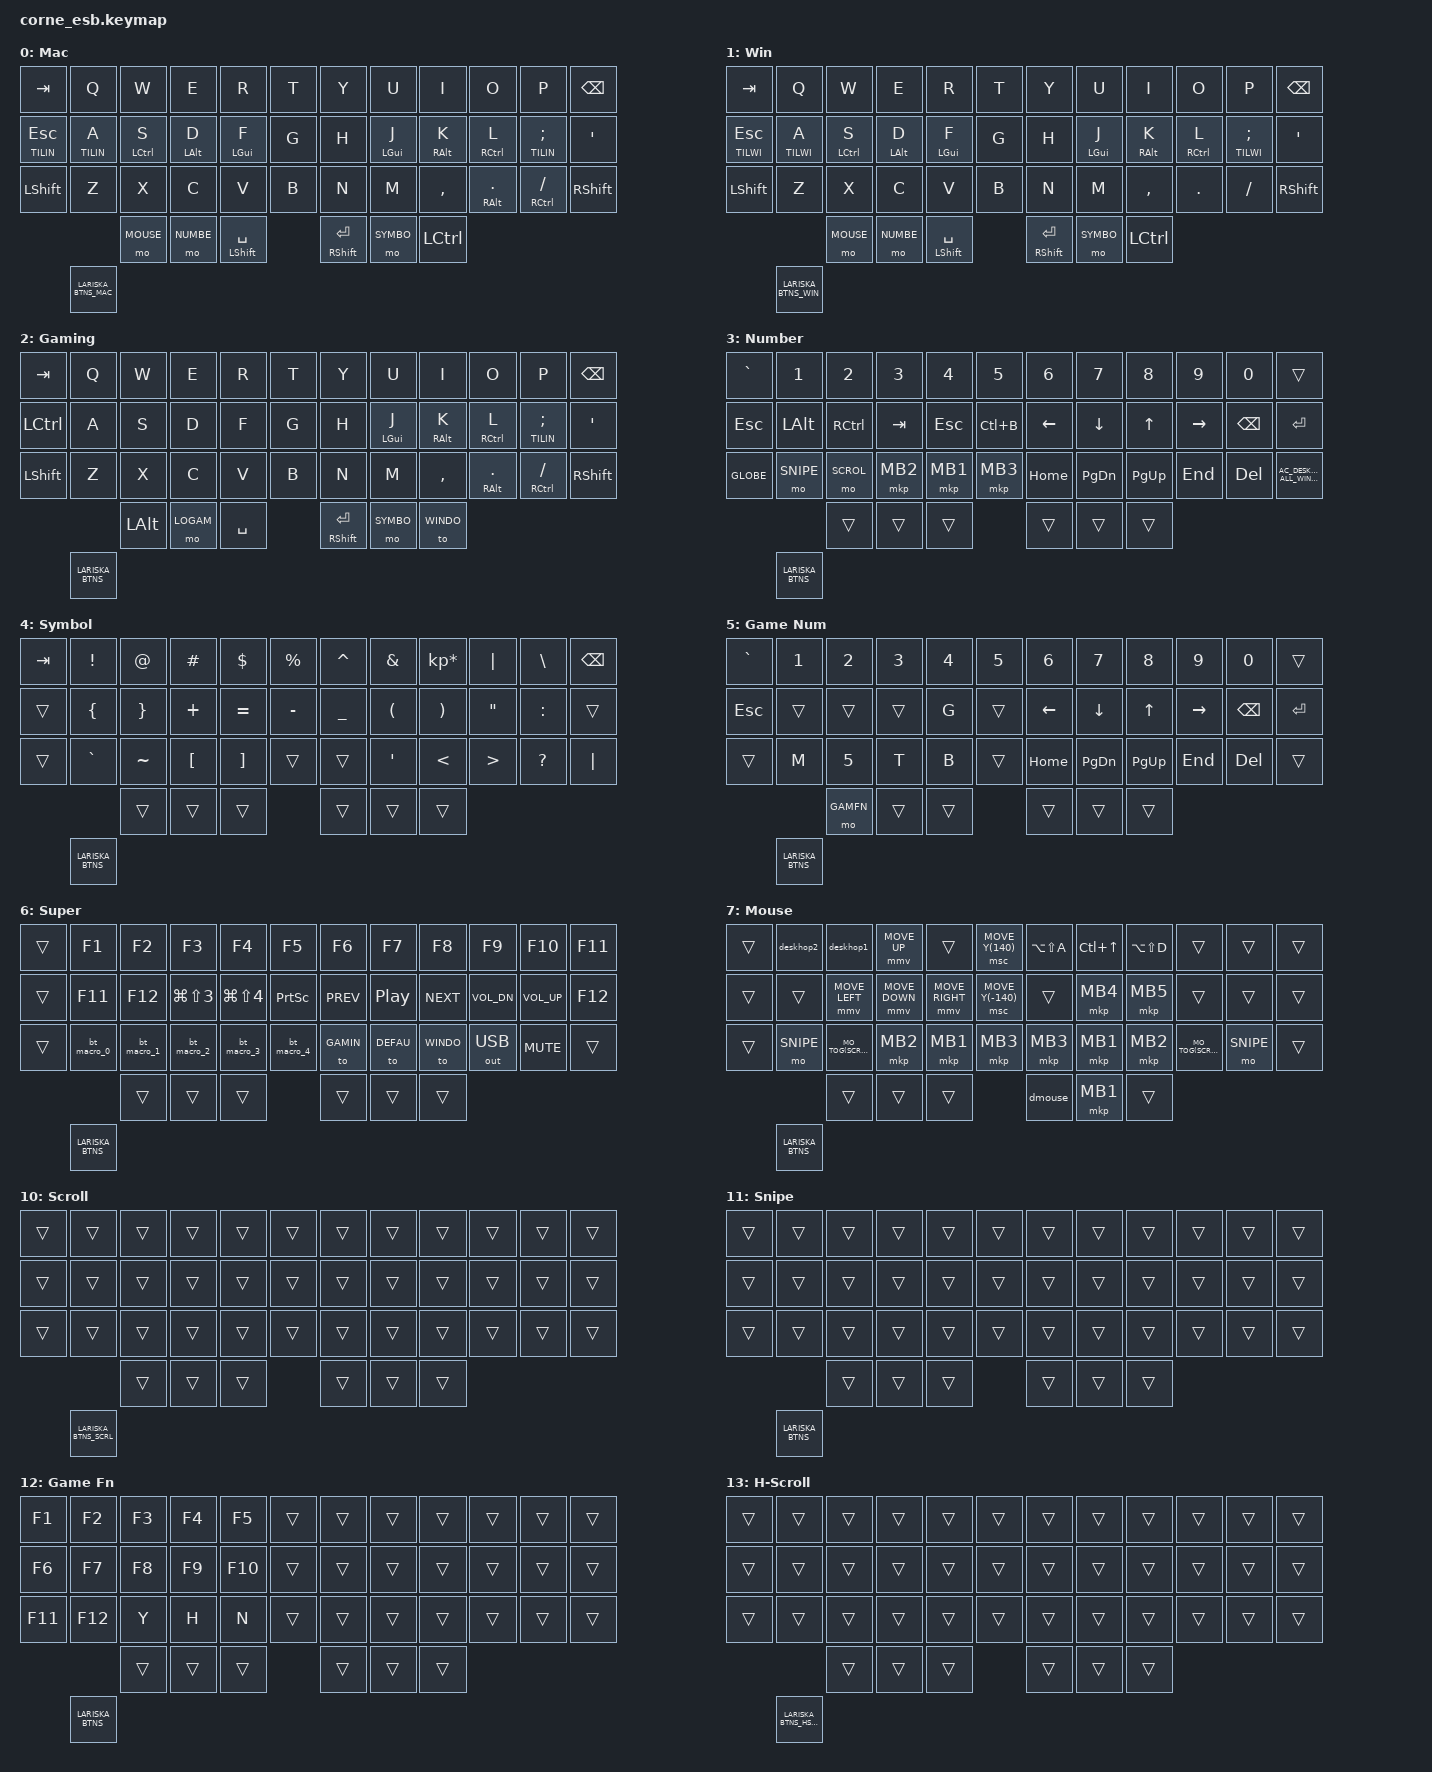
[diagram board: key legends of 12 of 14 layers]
#define ZMK_POINTING_DEFAULT_SCRL_VAL 100

#include <behaviors.dtsi>
#include <dt-bindings/zmk/keys.h>
#include <dt-bindings/zmk/bt.h>
#include <dt-bindings/zmk/ext_power.h>
#include <dt-bindings/zmk/mouse.h>
#include <dt-bindings/zmk/outputs.h>
#include <dt-bindings/zmk/pointing.h>
#include <behaviors/mouse_keys.dtsi>

#define MO_TOG(layer) &mo_tog layer layer

#define DEFAU 0
#define WINDO 1
#define GAMIN 2
#define NUMBE 3
#define SYMBO 4
#define LOGAM 5
#define SUPER 6
#define MOUSE 7
#define TILIN 8
#define TILWI 9
#define SCROL 10
#define SNIPE 11
#define GAMFN 12
#define HSCRL 13

/* Corne key positions: row 0 = 0-11, row 1 = 12-23, row 2 = 24-35,
 * thumbs = 36-38 (left) / 39-41 (right).
 *
 * Lariska (optional) mouse button bindings appended to every layer
 * (positions 42-46): LCLK RCLK MCLK MB4 MB5.
 * MB4 is a tap-dance: tap = normal MB4 click, hold = momentary SCROL layer
 * (fast 4x vertical scroll on the encoder), double-tap = OS overview (mission
 * control on mac / task view on win).
 * MB5 is a hold-tap: tap = normal MB5 click, hold = momentary tiling layer
 * (alt-tab on the scroll wheel) -- instant, no tap-dance delay.
 * Holding MB4 + MB5 together activates the horizontal-scroll layer (HSCRL):
 * the second button is &trans on the first button's layer, so it falls through
 * to its base hold; with both holds down, conditional_layers turns on HSCRL.
 * When no Lariska is paired these positions simply never fire. */
/* L/R clicks use &bd (drain-aware, zmk-behavior-button-direct, declared in
 * corne_esb_addr.dtsi): a release lost over ESB self-heals on the next click
 * instead of sticking the HID button until dongle restart. */
#define LARISKA_BTNS       &bd LCLK &bd RCLK &mkp MCLK &mo_mkp SCROL MB4 &mkp MB5
#define LARISKA_BTNS_MAC   &bd LCLK &bd RCLK &mkp MCLK &td_mb4_mac &mo_mkp TILIN MB5
#define LARISKA_BTNS_WIN   &bd LCLK &bd RCLK &mkp MCLK &td_mb4_win &mo_mkp TILWI MB5
/* Inside the held tiling layers MB4 is &trans so a second MB4 press falls
 * through to the base MB4 hold (mo_mkp SCROL via the tap-dance); SCROL + the
 * tiling layer then trigger HSCRL through conditional_layers.
 * (OS overview now lives on the MB4 double-tap.) */
#define LARISKA_BTNS_TILIN &bd LCLK &bd RCLK &mkp MCLK &trans &mkp MB5
#define LARISKA_BTNS_TILWI &bd LCLK &bd RCLK &mkp MCLK &trans &mkp MB5
/* Inside the SCROL layer MB5 is &trans so it falls through to the base MB5
 * hold (mo_mkp TILIN/TILWI); SCROL + tiling then trigger HSCRL. */
#define LARISKA_BTNS_SCRL  &bd LCLK &bd RCLK &mkp MCLK &mo_mkp SCROL MB4 &trans
/* MB4 + MB5 held: both fall through (&trans) so the holds persist. */
#define LARISKA_BTNS_HSCRL &bd LCLK &bd RCLK &mkp MCLK &trans &trans

/ {
    /* One discrete REL_WHEEL tick per Lariska encoder detent via
     * zmk-behavior-stepped-scroll. stepped_scroll is defined in the addr dtsi;
     * stepped_scroll_il (dongle overlay) routes its events to HID. */
    lariska_scroll: lariska_scroll {
        compatible = "zmk,behavior-sensor-rotate";
        #sensor-binding-cells = <0>;
        bindings = <&stepped_scroll (-1)>, <&stepped_scroll 1>;
    };
    /* Fast vertical scroll (4x) for the MB4-hold scroll layer: 4 REL_WHEEL
     * ticks per detent, same direction as lariska_scroll. */
    lariska_scroll_4x: lariska_scroll_4x {
        compatible = "zmk,behavior-sensor-rotate";
        #sensor-binding-cells = <0>;
        bindings = <&stepped_scroll (-4)>, <&stepped_scroll 4>;
    };
    /* Horizontal mouse-wheel scroll for the MB4+MB5 hscroll layer. One
     * REL_HWHEEL tick per detent via stepped_hscroll (addr dtsi / overlay). */
    lariska_hscroll: lariska_hscroll {
        compatible = "zmk,behavior-sensor-rotate";
        #sensor-binding-cells = <0>;
        bindings = <&stepped_hscroll (-1)>, <&stepped_hscroll 1>;
    };
    alt_tab_encoder: alt_tab_encoder {
        compatible = "zmk,behavior-sensor-rotate";
        label = "ALT_TAB_ENC";
        #sensor-binding-cells = <0>;
        tap-ms = <5>;
        bindings = <&swap_enc_rev>, <&swap_enc>;
    };
    /* Mouse-wheel space navigation for the Mac tiling layer. */
    lariska_ws: lariska_ws {
        compatible = "zmk,behavior-sensor-rotate";
        label = "LARISKA_WS";
        #sensor-binding-cells = <0>;
        tap-ms = <5>;
        bindings = <&kp LC(RIGHT)>, <&kp LC(LEFT)>;
    };
    rot_kp: sensor_rotate_kp {
        compatible = "zmk,behavior-sensor-rotate-var";
        #sensor-binding-cells = <2>;
        bindings = <&kp>, <&kp>;
    };

    conditional_layers {
        compatible = "zmk,conditional-layers";

        tri_layer {
            if-layers = <NUMBE SYMBO>;
            then-layer = <SUPER>;
        };

        tri_layer_gaming {
            if-layers = <SYMBO LOGAM>;
            then-layer = <SUPER>;
        };

        /* MB4 (SCROL) + MB5 (tiling) held together -> horizontal scroll. */
        hscroll_mac {
            if-layers = <SCROL TILIN>;
            then-layer = <HSCRL>;
        };

        hscroll_win {
            if-layers = <SCROL TILWI>;
            then-layer = <HSCRL>;
        };
    };

    behaviors {
        sk_forever: sk_forever {
            compatible = "zmk,behavior-sticky-key";
            #binding-cells = <1>;
            bindings = <&kp>;
            ignore-modifiers;
            release-after-ms = <600000>;
        };

        hm: homerow_mods {
            compatible = "zmk,behavior-hold-tap";
            label = "HOMEROW_MODS";
            #binding-cells = <2>;
            tapping-term-ms = <200>;
            quick-tap-ms = <0>;
            flavor = "tap-preferred";
            bindings = <&kp>, <&kp>;
        };

        hk: homerow_hold {
            compatible = "zmk,behavior-hold-tap";
            label = "HOLD_MOD";
            #binding-cells = <2>;
            tapping-term-ms = <150>;
            quick-tap-ms = <0>;
            flavor = "hold-preferred";
            bindings = <&kp>, <&kp>;
        };

        hs: hold_custom {
            compatible = "zmk,behavior-hold-tap";
            label = "HOLD_CUSTOM";
            #binding-cells = <2>;
            tapping-term-ms = <500>;
            quick-tap-ms = <0>;
            flavor = "tap-preferred";
            bindings = <&kp>, <&kp>;
        };

        mo_tog: behavior_mo_tog {
            compatible = "zmk,behavior-hold-tap";
            #binding-cells = <2>;
            flavor = "hold-preferred";
            tapping-term-ms = <200>;
            bindings = <&mo>, <&tog>;
        };

        /* Hold = momentary layer, tap = mouse-button click (for MB5). */
        mo_mkp: behavior_mo_mkp {
            compatible = "zmk,behavior-hold-tap";
            label = "MO_MKP";
            #binding-cells = <2>;
            flavor = "hold-preferred";
            tapping-term-ms = <150>;
            quick-tap-ms = <0>;
            bindings = <&mo>, <&mkp>;
        };

        w1: w1 {
            compatible = "zmk,behavior-tri-state";
            label = "WIN OPEN 1";
            #binding-cells = <0>;
            bindings = <&kt LGUI>, <&kp N1>, <&kt LGUI>;
        };

        w2: w2 {
            compatible = "zmk,behavior-tri-state";
            label = "WIN OPEN 2";
            #binding-cells = <0>;
            bindings = <&kt LGUI>, <&kp N2>, <&kt LGUI>;
        };

        w3: w3 {
            compatible = "zmk,behavior-tri-state";
            label = "WIN OPEN 3";
            #binding-cells = <0>;
            bindings = <&kt LGUI>, <&kp N3>, <&kt LGUI>;
        };

        w4: w4 {
            compatible = "zmk,behavior-tri-state";
            label = "WIN OPEN 4";
            #binding-cells = <0>;
            bindings = <&kt LGUI>, <&kp N4>, <&kt LGUI>;
        };

        w5: w5 {
            compatible = "zmk,behavior-tri-state";
            label = "WIN OPEN 5";
            #binding-cells = <0>;
            bindings = <&kt LGUI>, <&kp N5>, <&kt LGUI>;
        };

        w6: w6 {
            compatible = "zmk,behavior-tri-state";
            label = "WIN OPEN 6";
            #binding-cells = <0>;
            bindings = <&kt LGUI>, <&kp N6>, <&kt LGUI>;
        };

        w7: w7 {
            compatible = "zmk,behavior-tri-state";
            label = "WIN OPEN 7";
            #binding-cells = <0>;
            bindings = <&kt LGUI>, <&kp N7>, <&kt LGUI>;
        };

        w8: w8 {
            compatible = "zmk,behavior-tri-state";
            label = "WIN OPEN 8";
            #binding-cells = <0>;
            bindings = <&kt LGUI>, <&kp N8>, <&kt LGUI>;
        };

        w9: w9 {
            compatible = "zmk,behavior-tri-state";
            label = "WIN OPEN 9";
            #binding-cells = <0>;
            bindings = <&kt LGUI>, <&kp N9>, <&kt LGUI>;
        };

        td_alt: tap_dance_0 {
            compatible = "zmk,behavior-tap-dance";
            #binding-cells = <0>;
            tapping-term-ms = <200>;
            bindings = <&kp LALT>, <&to WINDO>;
        };

        td_mo: tap_dance_1 {
            compatible = "zmk,behavior-tap-dance";
            #binding-cells = <0>;
            tapping-term-ms = <200>;
            bindings = <MO_TOG(MOUSE)>, <&to GAMIN>;
        };

        /* Lariska MB4 tap-dance: tap = MB4 click, hold = momentary SCROL layer
         * (fast 4x vertical scroll), double-tap = OS overview (mission control /
         * task view). Binding 0 is the existing hold-tap, so it still resolves
         * tap-vs-hold; binding 1 fires only on the second tap. The tap-dance
         * delay lands on the scroll layer (not on MB5's alt-tab, now instant). */
        td_mb4_mac: td_mb4_mac {
            compatible = "zmk,behavior-tap-dance";
            #binding-cells = <0>;
            tapping-term-ms = <200>;
            bindings = <&mo_mkp SCROL MB4>, <&kp LC(UP)>;
        };
        td_mb4_win: td_mb4_win {
            compatible = "zmk,behavior-tap-dance";
            #binding-cells = <0>;
            tapping-term-ms = <200>;
            bindings = <&mo_mkp SCROL MB4>, <&kp LG(TAB)>;
        };

        /* Forward alt-tab on the windows tiling layer. hold-start makes swap and
         * swap_rev share a ref-counted LALT, so either can start the alt-tab from
         * cold and they compose while cycling. ignores the swap_rev key (pos 26)
         * and Lariska LCLK/RCLK/MCLK (42-44) so a click doesn't end the hold. */
        swap: swapper {
            compatible = "zmk,behavior-tri-state";
            label = "SWAPPER";
            #binding-cells = <0>;
            bindings = <&kp LALT>, <&kp TAB>, <&kp LALT>;
            hold-start;
            ignored-key-positions = <26 42 43 44>;
        };
        /* Reverse alt-tab (Shift+Tab); shares the LALT hold with swap (pos 14). */
        swap_rev: swap_rev {
            compatible = "zmk,behavior-tri-state";
            label = "SWAPPER_REV";
            #binding-cells = <0>;
            bindings = <&kp LALT>, <&kp LS(TAB)>, <&kp LALT>;
            hold-start;
            ignored-key-positions = <14 42 43 44>;
        };

        /* Forward cmd-tab on the Mac tiling layer; ignores swapmac_rev (pos 25). */
        swapmac: swappermac {
            compatible = "zmk,behavior-tri-state";
            label = "SWAPPERMAC";
            #binding-cells = <0>;
            bindings = <&kp LGUI>, <&kp TAB>, <&kp LGUI>;
            hold-start;
            ignored-key-positions = <25 42 43 44>;
        };
        /* Reverse cmd-tab; shares the LGUI hold with swapmac (pos 27). */
        swapmac_rev: swapmac_rev {
            compatible = "zmk,behavior-tri-state";
            label = "SWAPPERMAC_REV";
            #binding-cells = <0>;
            bindings = <&kp LGUI>, <&kp LS(TAB)>, <&kp LGUI>;
            hold-start;
            ignored-key-positions = <27 42 43 44>;
        };

        /* Encoder-driven alt-tab for the Lariska wheel on the Windows tiling layer.
         * swap_enc / swap_enc_rev share the alt-hold via the sensor's virtual key
         * position, so alt-tab engages no matter which way the wheel turns first.
         * ignored-key-positions 42-44 = Lariska LCLK/RCLK/MCLK, so clicking
         * mid-cycle doesn't interrupt the hold. */
        swap_enc: swap_enc {
            compatible = "zmk,behavior-tri-state";
            label = "SWAPPER_ENC";
            #binding-cells = <0>;
            bindings = <&kt LALT>, <&kp TAB>, <&kt LALT>;
            ignored-key-positions = <42 43 44>;
        };
        swap_enc_rev: swap_enc_rev {
            compatible = "zmk,behavior-tri-state";
            label = "SWAPPER_ENC_REV";
            #binding-cells = <0>;
            bindings = <&kt LALT>, <&kp LS(TAB)>, <&kt LALT>;
            ignored-key-positions = <42 43 44>;
        };
    };

    macros {
        bt_macro_0: bt_macro_0 {
            label = "esb_macro_0";
            compatible = "zmk,behavior-macro";
            #binding-cells = <0>;
            wait-ms = <0>;
            tap-ms = <0>;
            bindings = <&to DEFAU>;
        };

        bt_macro_1: bt_macro_1 {
            label = "esb_macro_1";
            compatible = "zmk,behavior-macro";
            #binding-cells = <0>;
            wait-ms = <0>;
            tap-ms = <0>;
            bindings = <&to WINDO>;
        };

        bt_macro_2: bt_macro_2 {
            label = "esb_macro_2";
            compatible = "zmk,behavior-macro";
            #binding-cells = <0>;
            wait-ms = <0>;
            tap-ms = <0>;
            bindings = <&to GAMIN>;
        };

        bt_macro_3: bt_macro_3 {
            label = "esb_macro_3";
            compatible = "zmk,behavior-macro";
            #binding-cells = <0>;
            wait-ms = <0>;
            tap-ms = <0>;
            bindings = <&out OUT_USB>;
        };

        bt_macro_4: bt_macro_4 {
            label = "esb_macro_4";
            compatible = "zmk,behavior-macro";
            #binding-cells = <0>;
            wait-ms = <0>;
            tap-ms = <0>;
            bindings = <&none>;
        };

        dmouse: dmouse {
            label = "deactivate_mouse";
            compatible = "zmk,behavior-macro";
            #binding-cells = <0>;
            wait-ms = <0>;
            tap-ms = <0>;
            bindings = <&mo MOUSE>, <&mo SCROL>, <&mo SNIPE>;
        };

        deskhop1: deskhop1 {
            label = "deskhop1";
            compatible = "zmk,behavior-macro";
            #binding-cells = <0>;
            wait-ms = <0>;
            tap-ms = <0>;
            bindings = <&kp RC(RA(N1))>;
        };

        deskhop2: deskhop2 {
            label = "deskhop2";
            compatible = "zmk,behavior-macro";
            #binding-cells = <0>;
            wait-ms = <0>;
            tap-ms = <0>;
            bindings = <&kp RC(RA(N2))>;
        };
    };

    combos {
        compatible = "zmk,combos";

        /* X + C + V (positions 26 27 28) toggles gaming, only from the
         * windows base layer or gaming itself. */
        combo_gaming {
            timeout-ms = <50>;
            key-positions = <26 27 28>;
            bindings = <&tog GAMIN>;
            layers = <GAMIN WINDO>;
        };
    };

    keymap {
        compatible = "zmk,keymap";

        default_layer {
            label = "Mac";
            bindings = <
&kp TAB        &kp Q        &kp W        &kp E       &kp R       &kp T         &kp Y          &kp U       &kp I       &kp O         &kp P           &kp BSPC
&lt TILIN ESC  &lt TILIN A  &hm LCTRL S  &hm LALT D  &hm LGUI F  &kp G         &kp H          &hm LGUI J  &hm RALT K  &hm RCTRL L   &lt TILIN SEMI  &kp SQT
&kp LSHFT      &kp Z        &kp X        &kp C       &kp V       &kp B         &kp N          &kp M       &kp COMMA   &hm RALT DOT  &hm RCTRL FSLH  &kp RSHFT
                                &mo MOUSE   &mo NUMBE  &hm LSHFT SPACE    &hk RSHFT RET  &mo SYMBO  &kp LCTRL
            LARISKA_BTNS_MAC
            >;
            sensor-bindings = <&lariska_scroll>;
        };

        windows {
            label = "Win";
            bindings = <
&kp TAB        &kp Q        &kp W        &kp E       &kp R       &kp T         &kp Y          &kp U       &kp I       &kp O         &kp P           &kp BSPC
&lt TILWI ESC  &lt TILWI A  &hm LCTRL S  &hm LALT D  &hm LGUI F  &kp G         &kp H          &hm LGUI J  &hm RALT K  &hm RCTRL L   &lt TILWI SEMI  &kp SQT
&kp LSHFT      &kp Z        &kp X        &kp C       &kp V       &kp B         &kp N          &kp M       &kp COMMA   &kp DOT       &kp FSLH        &kp RSHFT
                                &mo MOUSE   &mo NUMBE  &hm LSHFT SPACE    &hk RSHFT RET  &mo SYMBO  &kp LCTRL
            LARISKA_BTNS_WIN
            >;
            sensor-bindings = <&lariska_scroll>;
        };

        gaming_layer {
            label = "Gaming";
            bindings = <
&kp TAB    &kp Q  &kp W  &kp E  &kp R  &kp T        &kp Y      &kp U       &kp I       &kp O         &kp P           &kp BSPC
&kp LCTRL  &kp A  &kp S  &kp D  &kp F  &kp G        &kp H      &hm LGUI J  &hm RALT K  &hm RCTRL L   &lt TILIN SEMI  &kp SQT
&kp LSHFT  &kp Z  &kp X  &kp C  &kp V  &kp B        &kp N      &kp M       &kp COMMA   &hm RALT DOT  &hm RCTRL FSLH  &kp RSHFT
                     &kp LALT  &mo LOGAM  &kp SPACE    &hk RSHFT RET  &mo SYMBO  &to WINDO
            LARISKA_BTNS
            >;
            sensor-bindings = <&lariska_scroll>;
        };

        lower_layer {
            label = "Number";
            bindings = <
&kp GRAVE  &kp N1     &kp N2     &kp N3    &kp N4    &kp N5       &kp N6    &kp N7     &kp N8     &kp N9     &kp N0    &trans
&kp ESC    &kp LALT   &kp RCTRL  &kp TAB   &kp ESC   &kp LC(B)    &kp LEFT  &kp DOWN   &kp UP     &kp RIGHT  &kp BSPC  &kp RET
&kp GLOBE  &mo SNIPE  &mo SCROL  &mkp MB2  &mkp MB1  &mkp MB3     &kp HOME  &kp PG_DN  &kp PG_UP  &kp END    &kp DEL   &kp C_AC_DESKTOP_SHOW_ALL_WINDOWS
                                  &trans  &trans  &trans    &trans  &trans  &trans
            LARISKA_BTNS
            >;
            sensor-bindings = <&lariska_scroll>;
        };

        raise_layer {
            label = "Symbol";
            bindings = <
&kp TAB  &kp EXCL   &kp AT     &kp HASH  &kp DLLR   &kp PRCNT    &kp CARET  &kp AMPS  &kp KP_MULTIPLY  &kp PIPE  &kp BSLH   &kp BSPC
&trans   &kp LBRC   &kp RBRC   &kp PLUS  &kp EQUAL  &kp MINUS    &kp UNDER  &kp LPAR  &kp RPAR         &kp DQT   &kp COLON  &trans
&trans   &kp GRAVE  &kp TILDE  &kp LBKT  &kp RBKT   &trans       &trans     &kp SQT   &kp LT           &kp GT    &kp QMARK  &kp PIPE
                                  &trans  &trans  &trans    &trans  &trans  &trans
            LARISKA_BTNS
            >;
            sensor-bindings = <&lariska_scroll>;
        };

        gaming_lower {
            label = "Game Num";
            bindings = <
&kp GRAVE  &kp N1  &kp N2  &kp N3  &kp N4  &kp N5    &kp N6    &kp N7     &kp N8     &kp N9     &kp N0    &trans
&kp ESC    &trans  &trans  &trans  &kp G   &trans    &kp LEFT  &kp DOWN   &kp UP     &kp RIGHT  &kp BSPC  &kp RET
&trans     &kp M   &kp N5  &kp T   &kp B   &trans    &kp HOME  &kp PG_DN  &kp PG_UP  &kp END    &kp DEL   &trans
                     &mo GAMFN  &trans  &trans    &trans  &trans  &trans
            LARISKA_BTNS
            >;
            sensor-bindings = <&lariska_scroll>;
        };

        super_layer {
            label = "Super";
            bindings = <
&trans  &kp F1       &kp F2       &kp F3          &kp F4          &kp F5         &kp F6      &kp F7     &kp F8      &kp F9        &kp F10       &kp F11
&trans  &kp F11      &kp F12      &kp LG(LS(N3))  &kp LG(LS(N4))  &kp PSCRN      &kp C_PREV  &kp C_PP   &kp C_NEXT  &kp C_VOL_DN  &kp C_VOL_UP  &kp F12
&trans  &bt_macro_0  &bt_macro_1  &bt_macro_2     &bt_macro_3     &bt_macro_4    &to GAMIN   &to DEFAU  &to WINDO   &out OUT_USB  &kp C_MUTE    &trans
                                     &trans  &trans  &trans    &trans  &trans  &trans
            LARISKA_BTNS
            >;
        };

        mouse_layer {
            label = "Mouse";
            bindings = <
&trans  &deskhop2  &deskhop1       &mmv MOVE_UP    &trans           &msc MOVE_Y(140)     &kp LA(LS(A))  &kp LC(UP)  &kp LA(LS(D))  &trans         &trans     &trans
&trans  &trans     &mmv MOVE_LEFT  &mmv MOVE_DOWN  &mmv MOVE_RIGHT  &msc MOVE_Y(-140)    &trans         &mkp MB4    &mkp MB5       &trans         &trans     &trans
&trans  &mo SNIPE  MO_TOG(SCROL)   &mkp MB2        &mkp MB1         &mkp MB3             &mkp MB3       &mkp MB1    &mkp MB2       MO_TOG(SCROL)  &mo SNIPE  &trans
                                      &trans  &trans  &trans    &dmouse  &mkp MB1  &trans
            LARISKA_BTNS
            >;
            /* Lariska encoder = volume on the mouse layer. */
            sensor-bindings = <&rot_kp C_VOL_DN C_VOL_UP>;
        };

        tiling_layer {
            label = "Tiling";
            bindings = <
&trans  &hs LC(LA(LS(N1))) LA(LS(N1))  &hs LC(LA(LS(N2))) LA(LS(N2))  &hs LC(LA(LS(N3))) LA(LS(N3))  &hs LC(LA(LS(N4))) LA(LS(N4))  &hs LC(LA(LS(N5))) LA(LS(N5))    &hs LC(LA(LS(N6))) LA(LS(N6))  &hs LC(LA(LS(N7))) LA(LS(N7))  &hs LC(LA(LS(N8))) LA(LS(N8))  &hs LC(LA(LS(N9))) LA(LS(N9))  &trans  &trans
&trans  &trans                         &kp LC(F4)                     &hs LC(LA(LS(E))) LA(LS(E))    &hs LC(LA(LS(R))) LA(LS(R))    &hs LC(LA(LS(T))) LA(LS(T))      &trans                         &trans                         &trans                         &trans                         &trans  &trans
&trans  &swapmac_rev                   &kp LS(LC(F4))                 &swapmac                       &trans                         &trans                           &trans                         &trans                         &trans                         &trans                         &trans  &trans
                                          &trans  &trans  &kp LG(SPACE)    &trans  &trans  &trans
            LARISKA_BTNS_TILIN
            >;
            sensor-bindings = <&lariska_ws>;
        };

        tiling_win_layer {
            label = "TWin";
            bindings = <
&trans  &w1            &w2        &w3                          &w4                          &w5                              &w6     &w7     &w8     &w9     &trans  &trans
&trans  &trans         &swap      &hs LC(LA(LS(E))) LA(LS(E))  &hs LC(LA(LS(R))) LA(LS(R))  &hs LC(LA(LS(T))) LA(LS(T))      &trans  &trans  &trans  &trans  &trans  &trans
&trans  &kp LA(LS(D))  &swap_rev  &kp LA(LS(D))                &trans                       &trans                           &trans  &trans  &trans  &trans  &trans  &trans
                                     &trans  &trans  &kp LGUI    &trans  &trans  &trans
            LARISKA_BTNS_TILWI
            >;
            sensor-bindings = <&alt_tab_encoder>;
        };

        scroll {
            label = "Scroll";
            bindings = <
&trans  &trans  &trans  &trans  &trans  &trans    &trans  &trans  &trans  &trans  &trans  &trans
&trans  &trans  &trans  &trans  &trans  &trans    &trans  &trans  &trans  &trans  &trans  &trans
&trans  &trans  &trans  &trans  &trans  &trans    &trans  &trans  &trans  &trans  &trans  &trans
                          &trans  &trans  &trans    &trans  &trans  &trans
            LARISKA_BTNS_SCRL
            >;
            /* Fast (4x) vertical scroll on the Lariska encoder. */
            sensor-bindings = <&lariska_scroll_4x>;
        };

        snipe {
            label = "Snipe";
            bindings = <
&trans  &trans  &trans  &trans  &trans  &trans    &trans  &trans  &trans  &trans  &trans  &trans
&trans  &trans  &trans  &trans  &trans  &trans    &trans  &trans  &trans  &trans  &trans  &trans
&trans  &trans  &trans  &trans  &trans  &trans    &trans  &trans  &trans  &trans  &trans  &trans
                          &trans  &trans  &trans    &trans  &trans  &trans
            LARISKA_BTNS
            >;
        };

        game_fn_layer {
            label = "Game Fn";
            bindings = <
&kp F1   &kp F2   &kp F3  &kp F4  &kp F5   &trans     &trans  &trans  &trans  &trans  &trans  &trans
&kp F6   &kp F7   &kp F8  &kp F9  &kp F10  &trans     &trans  &trans  &trans  &trans  &trans  &trans
&kp F11  &kp F12  &kp Y   &kp H   &kp N    &trans     &trans  &trans  &trans  &trans  &trans  &trans
                          &trans  &trans  &trans    &trans  &trans  &trans
            LARISKA_BTNS
            >;
            /* Lariska encoder = volume on the gaming fn layer. */
            sensor-bindings = <&rot_kp C_VOL_DN C_VOL_UP>;
        };

        hscroll_layer {
            label = "H-Scroll";
            bindings = <
&trans  &trans  &trans  &trans  &trans  &trans    &trans  &trans  &trans  &trans  &trans  &trans
&trans  &trans  &trans  &trans  &trans  &trans    &trans  &trans  &trans  &trans  &trans  &trans
&trans  &trans  &trans  &trans  &trans  &trans    &trans  &trans  &trans  &trans  &trans  &trans
                          &trans  &trans  &trans    &trans  &trans  &trans
            LARISKA_BTNS_HSCRL
            >;
            sensor-bindings = <&lariska_hscroll>;
        };
    };
};
